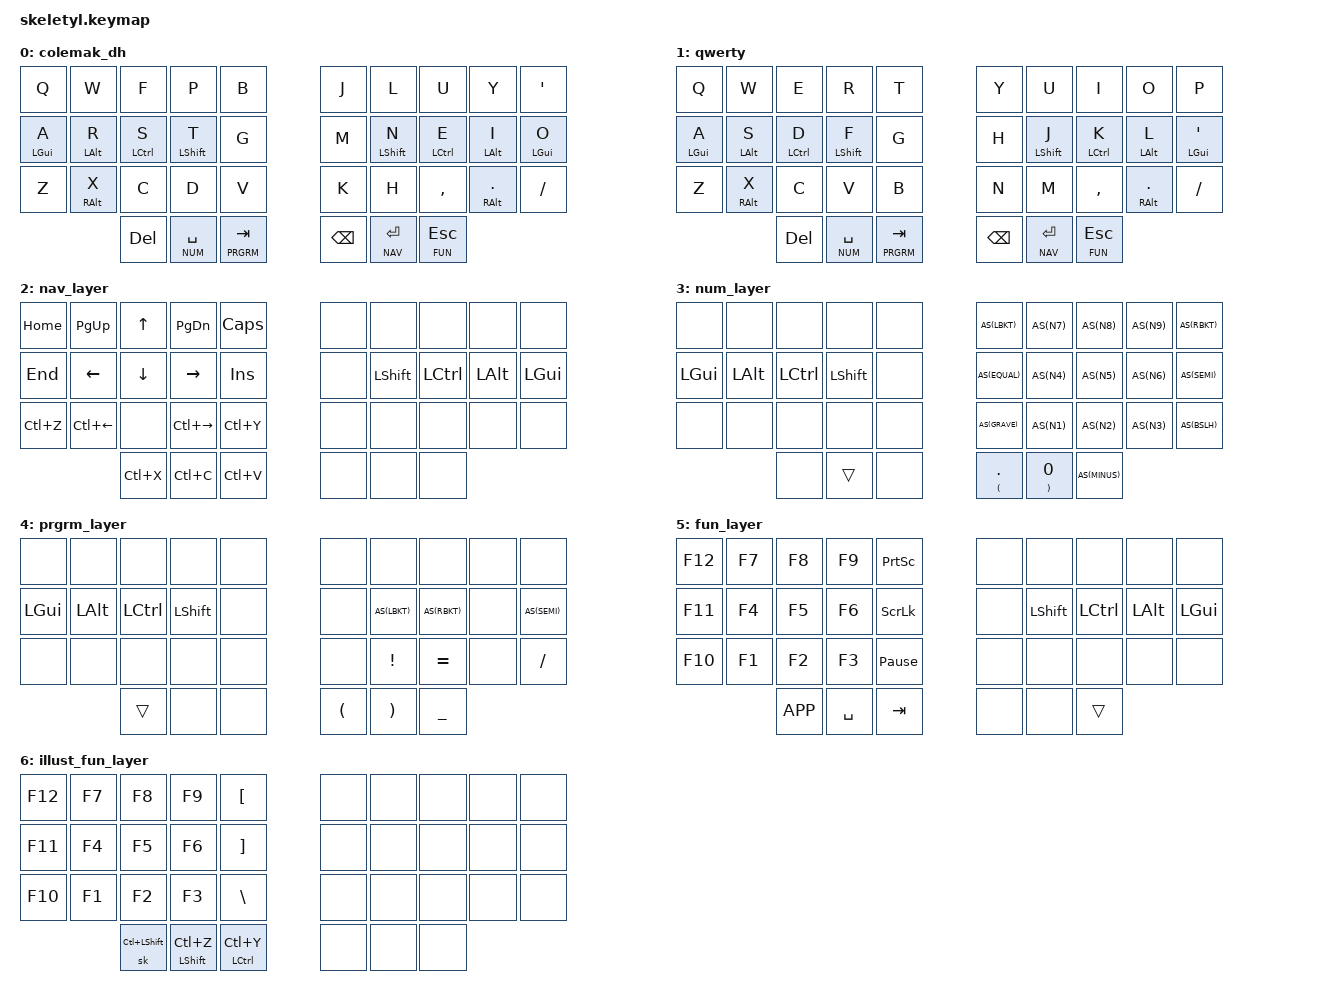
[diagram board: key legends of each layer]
#include <behaviors.dtsi>
#include <dt-bindings/zmk/keys.h>
#include <dt-bindings/zmk/bt.h>
#include <dt-bindings/zmk/outputs.h>
#include <zmk-helpers/helper.h>
#include <zmk-helpers/key-labels/36.h>

// Modified keymap based on personal experience, with some improvements based on Miryoku layout.

#define COLDH   0
#define QWERTY  1
#define NAV     2
#define NUM     3
#define PRGRM   4
#define FUN     5
#define ILLUST  6

#define KEYS_L LT0 LT1 LT2 LT3 LT4 LM0 LM1 LM2 LM3 LM4 LB0 LB1 LB2 LB3 LB4
#define KEYS_R RT0 RT1 RT2 RT3 RT4 RM0 RM1 RM2 RM3 RM4 RB0 RB1 RB2 RB3 RB4
#define HRL LM0 LM1 LM2 LM3 LB1
#define HRR RM1 RM2 RM3 RM4 RB3
#define THUMB_L 32 33 34    // 30 and 31 are disconnected
#define THUMB_R 35 36 37    // 34 and 35 are disconnected

#define AS(keycode) &as LS(keycode) keycode     // Autoshift Macro

&lt {
    tapping-term-ms = <175>;
};

/ {
    behaviors {
        as: auto_shift {
            compatible = "zmk,behavior-hold-tap";
            #binding-cells = <2>;
            tapping-term-ms = <175>;
            flavor = "tap-preferred";
            bindings = <&kp>, <&kp>;
        };
        lhm: left_homerow_mods {
            compatible = "zmk,behavior-hold-tap";
            #binding-cells = <2>;
            tapping-term-ms = <175>;
            // require-prior-idle-ms = <125>;
            flavor = "tap-preferred";
            bindings = <&kp>, <&kp>;
            hold-trigger-key-positions = <KEYS_R THUMB_R HRL>;
        };
        lhms: left_homerow_mod_shift {
            compatible = "zmk,behavior-hold-tap";
            #binding-cells = <2>;
            tapping-term-ms = <150>;
            flavor = "balanced";
            bindings = <&kp>, <&kp>;
            hold-trigger-key-positions = <KEYS_R THUMB_R LM3>;
            hold-trigger-on-release;
        };
        lhmp: left_homerow_mod_pinky {
            compatible = "zmk,behavior-hold-tap";
            #binding-cells = <2>;
            tapping-term-ms = <175>;
            // require-prior-idle-ms = <200>;
            flavor = "tap-preferred";
            bindings = <&kp>, <&kp>;
            hold-trigger-key-positions = <LM0 THUMB_R HRL>;
        };
        rhm: right_homerow_mods {
            compatible = "zmk,behavior-hold-tap";
            #binding-cells = <2>;
            tapping-term-ms = <175>;
            // require-prior-idle-ms = <125>;
            quick-tap-ms = <0>;
            flavor = "tap-preferred";
            bindings = <&kp>, <&kp>;
            hold-trigger-key-positions = <KEYS_L THUMB_L HRR>;
        };
        rhms: right_homerow_mods_shift {
            compatible = "zmk,behavior-hold-tap";
            #binding-cells = <2>;
            tapping-term-ms = <150>;
            quick-tap-ms = <0>;
            flavor = "balanced";
            bindings = <&kp>, <&kp>;
            hold-trigger-key-positions = <KEYS_L THUMB_L RM1>;
            hold-trigger-on-release;
        };
        rhmp: right_homerow_mod_pinky {
            compatible = "zmk,behavior-hold-tap";
            #binding-cells = <2>;
            tapping-term-ms = <175>;
            // require-prior-idle-ms = <200>;
            flavor = "tap-preferred";
            bindings = <&kp>, <&kp>;
            hold-trigger-key-positions = <RM4 THUMB_L HRR>;
        };
    };

    combos {
        compatible = "zmk,combos";

        // Combos for media player.
        // I often switch songs while drawing, so I assign the
        // combos on left hand side.

        combo_med_next {
            timeout-ms = <50>;
            key-positions = <2 3>;
            bindings = <&kp C_NEXT>;
        };
        combo_med_prev {
            timeout-ms = <50>;
            key-positions = <1 2>;
            bindings = <&kp C_PREV>;
        };
        combo_med_pp {
            timeout-ms = <50>;
            key-positions = <1 4>;
            bindings = <&kp C_PP>;
        };
        combo_med_stop {
            timeout-ms = <50>;
            key-positions = <1 3>;
            bindings = <&kp C_STOP>;
        };
        combo_med_vol_up {
            timeout-ms = <50>;
            key-positions = <2 13>;
            bindings = <&kp C_VOL_UP>;
        };
        combo_med_vol_dn {
            timeout-ms = <50>;
            key-positions = <3 12>;
            bindings = <&kp C_VOL_DN>;
        };
        combo_med_mute {
            timeout-ms = <50>;
            key-positions = <12 14>;
            bindings = <&kp C_MUTE>;
        };

        // combo for toggling illust layer
        combo_tg_illust {
            timeout-ms = <50>;
            key-positions = <21 22 23>;
            bindings = <&tog ILLUST>;
        };

        // Combo for toggling the QWERTY layout
        combo_tg_qwerty {
            timeout-ms = <50>;
            key-positions = <6 7 8>;
            bindings = <&tog QWERTY>;
        };

        // Combo for caps word
        combo_caps_word {
            timeout-ms = <50>;
            key-positions = <13 16>;
            bindings = <&caps_word>;
        };

        // Combo for bluetooth control
        // (i.e. switch among the devices).
        combo_bt_next {
            timeout-ms = <50>;
            key-positions = <27 28>;
            bindings = <&bt BT_NXT>;
        };
        combo_bt_prev {
            timeout-ms = <50>;
            key-positions = <26 27>;
            bindings = <&bt BT_PRV>;
        };
        combo_bt_clr_all {
            timeout-ms = <50>;
            key-positions = <0 9>;
            bindings = <&bt BT_CLR_ALL>;
        };
        combo_bt_out_tog {
            timeout-ms = <50>;
            key-positions = <4 5>;
            bindings = <&out OUT_TOG>;
        };

    };

    keymap {
        compatible = "zmk,keymap";

        colemak_dh {
            bindings = <
    &kp Q           &kp W           &kp F           &kp P               &kp B           &kp J       &kp L           &kp U           &kp Y               &kp SQT
    &lhmp LGUI A    &lhm LALT R     &lhms LCTRL S   &lhms LSHFT T       &kp G           &kp M       &rhms LSHFT N   &rhm LCTRL E    &rhm LALT I         &rhmp LGUI O
    &kp Z           &lhm RALT X     &kp C           &kp D               &kp V           &kp K       &kp H           &kp COMMA       &rhm RALT DOT       &kp FSLH
                                    &kp DEL         &lt NUM SPACE       &lt PRGRM TAB   &kp BSPC    &lt NAV RET     &lt FUN ESC
            >;
        };

        qwerty {
            bindings = <
    &kp Q           &kp W           &kp E           &kp R               &kp T           &kp Y       &kp U           &kp I           &kp O               &kp P
    &lhmp LGUI A    &lhm LALT S     &lhm LCTRL D    &lhms LSHFT F       &kp G           &kp H       &rhms LSHFT J   &rhm LCTRL K    &rhm LALT L         &rhmp LGUI SQT
    &kp Z           &lhm RALT X     &kp C           &kp V               &kp B           &kp N       &kp M           &kp COMMA       &rhm RALT DOT       &kp FSLH
                                    &kp DEL         &lt NUM SPACE       &lt PRGRM TAB   &kp BSPC    &lt NAV RET     &lt FUN ESC
            >;
        };

        nav_layer {
            bindings = <
    &kp HOME    &kp PG_UP       &kp UP      &kp PG_DN       &kp CAPS    &none       &none       &none       &none       &none
    &kp END     &kp LEFT        &kp DOWN    &kp RIGHT       &kp INS     &none       &kp LSHFT   &kp LCTRL   &kp LALT    &kp LGUI
    &kp LC(Z)   &kp LC(LEFT)    &none       &kp LC(RIGHT)   &kp LC(Y)   &none       &none       &none       &none       &none
                                &kp LC(X)   &kp LC(C)       &kp LC(V)   &none       &none       &none     
            >;
        };

        num_layer {
            bindings = <
    &none       &none       &none       &none       &none       AS(LBKT)        AS(N7)      AS(N8)      AS(N9)  AS(RBKT)
    &kp LGUI    &kp LALT    &kp LCTRL   &kp LSHFT   &none       AS(EQUAL)       AS(N4)      AS(N5)      AS(N6)  AS(SEMI)
    &none       &none       &none       &none       &none       AS(GRAVE)       AS(N1)      AS(N2)      AS(N3)  AS(BSLH)
                            &none       &trans      &none       &as LPAR DOT    &as RPAR N0 AS(MINUS)
            >;
        };

       prgrm_layer {
           bindings = <
    &none       &none       &none       &none       &none       &none   &none       &none       &none   &none
    &kp LGUI    &kp LALT    &kp LCTRL   &kp LSHFT   &none       &none   AS(LBKT)    AS(RBKT)    &none   AS(SEMI)
    &none       &none       &none       &none       &none       &none   &kp EXCL    &kp EQUAL   &none   &kp FSLH
                            &trans      &none       &none       &kp LPAR    &kp RPAR    &kp UNDER
            >;
        };

        fun_layer {
            bindings = <
    &kp F12 &kp F7  &kp F8      &kp F9      &kp PSCRN       &none   &none       &none       &none       &none
    &kp F11 &kp F4  &kp F5      &kp F6      &kp SLCK        &none   &kp LSHFT   &kp LCTRL   &kp LALT    &kp LGUI
    &kp F10 &kp F1  &kp F2      &kp F3      &kp PAUSE_BREAK &none   &none       &none       &none       &none
                    &kp K_APP   &kp SPACE   &kp TAB         &none   &none       &trans
            >;
        };

        illust_fun_layer {
            bindings = <
    &kp F12 &kp F7  &kp F8          &kp F9          &kp LBKT        &none   &none   &none   &none   &none
    &kp F11 &kp F4  &kp F5          &kp F6          &kp RBKT        &none   &none   &none   &none   &none
    &kp F10 &kp F1  &kp F2          &kp F3          &kp BSLH        &none   &none   &none   &none   &none
                    &sk LC(LSHFT)   &mt LSHFT LC(Z) &mt LCTRL LC(Y) &none   &none   &none
            >;
        };

    };
};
